# dm64lc_cslr_prev_001 register map
Vendor: Texas Instruments
Peripheral module from a debugger description file.
Registers are 32-bit, access not given, reset 0x0 unless marked. A register's access mark holds for its fields unless they carry their own. Offsets are as the file gives them; lines under a group give offsets from that group; [hi:lo] are bit positions; {n}, {i} and the like mark numbered series; 'fields as' and 'values as' point back to an identical list; <NAME> marks a mode.

## PREV — Preview Engine (spec vesion: 1.00.w.33)
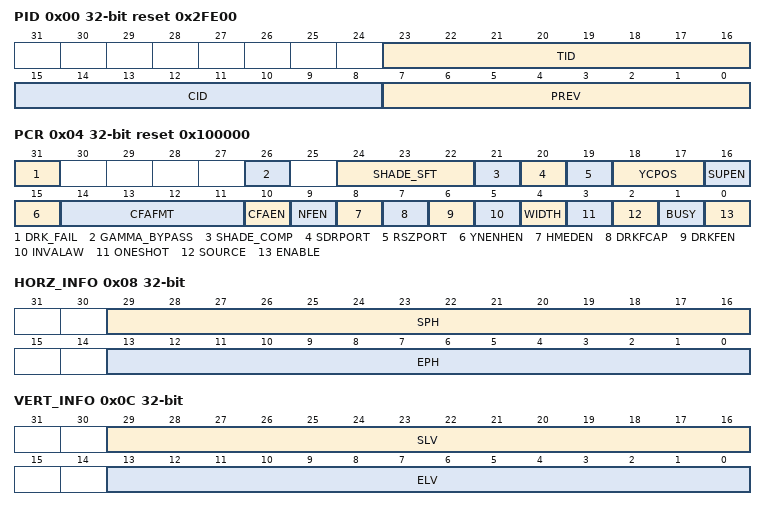
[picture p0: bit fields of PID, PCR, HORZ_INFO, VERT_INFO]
0x00 PID reset 0x2FE00 — Peripheral Revision and Class Information
  [23:16] TID ro — Peripheral Identificiation Preview Engine
  [15:8] CID ro — Class Identification Video Processing Front End (VPFE)
  [7:0] PREV ro — Peripheral Revision Number Initial Revision
0x04 PCR reset 0x100000 — Peripheral Control Register
  [31] DRK_FAIL rw — Dark frame subtract fail status Write 1 to clear this bit: dark frame subtract for current frame is abandoned, dark frame subtract resumes for next frame (but bit is not cleared unless explicitly done by firmware)
    0=PASS (pass flag); 1=FAIL (failed flag)
  [26] GAMMA_BYPASS rw — Gamma table bypass
    0=NO_BYPASS (Gamma tables not bypassed); 1=BYPASS (gamma tables are bypassed (output is 8 MSB or 10-bit input))
  [24:22] SHADE_SFT rw — Shading compensation right shift after multiplication 0-7: bits
  [21] SHADE_COMP rw — Shading compensation enable instead of dark frame The 8-bit value loaded from SDRAM is multiplied with the current pixel instead of subtracting it. Note that the dark frame subtract needs to be enabled in addition to this bit being active to perform shading compensation
    0=DISABLE; 1=ENABLE
  [20] SDRPORT rw — SDRAM port for the output of preview
    0=DISABLE; 1=ENABLE
  [19] RSZPORT rw — Resizer port enable (for input to resizer) Controls whether or not SDRAM output data is forwarded to the resizer input port. This control bit does not depend on the state of the SDRPORT bit above. Data is simultaneously written to SDRAM (if SDRPORT bit is set) while sending the same data to the resizer as input. Note that the CCDC is also capable or directly writing to the resizer input port. The CCDC setting takes precedence over the preview engine setting.
    0=DISABLE; 1=ENABLE
  [18:17] YCPOS rw — YC position
    0=YCRYCB (Y1(31:24) Cr0(23:16) Y0(15:8) Cb0(7:0)); 1=YCBYCR (Y1(31:24) Cb0(23:16) Y0(15:8) Cr0(7:0)); 2=CBYCRY (Cb0(31:24) Y1(23:16) Cr(15:8) Y0(7:0)); 3=CRYCBY (Cr0(31:24) Y1(23:16) Cb0(15:8) Y0(7:0))
  [16] SUPEN rw — Color suppression
    0=DISABLE; 1=ENABLE
  [15] YNENHEN rw — Non-linear enhancer
    0=DISABLE; 1=ENABLE
  [14:11] CFAFMT rw — CFA format
    0=CONV_BAYER (Conventional Bayer pattern); 1=RSV (RESERVED); 2=RSV (RESERVED); 3=V_AND_H_2X_DNSAMPLE (Vertical and horizontal 2x downsample); 4=RSV (RESERVED); 5=RSV (RESERVED)
  [10] CFAEN rw — CFA enable
    0=DISABLE; 1=ENABLE
  [9] NFEN rw — Noise filter (no register impact)
    0=DISABLE; 1=ENABLE
  [8] HMEDEN rw — Horizontal median filter (no register impact)
    0=DISABLE; 1=ENABLE
  [7] DRKFCAP rw — Dark frame capture
    0=NORMAL (normal processing); 1=CAPT_DK_FRM (capture dark frame)
  [6] DRKFEN rw — Subtract dark frame
    0=DISABLE; 1=ENABLE
  [5] INVALAW rw — Inverse A-law
    0=DISABLE; 1=ENABLE
  [4] WIDTH rw — Input data width
    0=10_BITWIDE; 1=8_BITWIDE
  [3] ONESHOT rw — One shot mode *If this bit is set to 1, it will be reset to 0 after the ENABLE bit is asserted.
    0=CONTINUOUS_VIA_VPORT (Continuous mode (via the video port)); 1=ONESHOTMODE
  [2] SOURCE rw — Input source *If this bit is set to 1, it will be reset to 0 after the ENABLE bit is asserted.
    0=VPORT_VIA_CCDC (Video port (via the CCDC)); 1=SDRAM
  [1] BUSY ro — Busy bit
    0=NOTBUSY (Preview engine is not busy); 1=BUSY (Preview engine is busy)
  [0] ENABLE rw — Enable bit *If the ONESHOT or SOURCE bit is 1, this bit will be reset to 0 after it is asserted.
    0=PREV_DISABLE (Preview engine is disabled); 1=PREV_ENABLE (Preview engine is enabled)
0x08 HORZ_INFO — Horizontal information/setup
  [29:16] SPH rw — Start pixel horizontal
  [13:0] EPH rw — End pixel horizontal The input width of the preview engine must be a multiple of the average count multiplied by the least common multiple of the odd distance and even distance of the AVE register settings. HORZ_INFO.EPH - HORZ_INFO.EPH + 1) MOD ((1 << AVE.COUNT) * LeastCommonMultiple(AVE.ODDDIST+1, AVE.EVENDIST+1)) = 0
0x0C VERT_INFO — Vertical information/setup
  [29:16] SLV rw — Start line vertical
  [13:0] ELV rw — End line vertical
0x10 RSDR_ADDR rw — Read address from SDRAM
  [31:0] RADR — Read Address Specifies the initial address of the frame that is to be fetched from SDRAM The lower 5 bits of this register are always treated as zeroes - the starting address should be 32-byte aligned * This field can be altered even when the preview engine is busy. Change will take place only for the next frame. However, note that reading this register will always give the latest value.
0x14 RADR_OFFSET — Line offset for the read data
  [15:0] OFFSET rw — Line offset Specifies the offset for each line relative to the previous line The lower 5 bits of this register are always treated as zeroes - the offset should be 32-byte aligned * This field can be altered even when the preview engine is busy. Change will take place only for the next frame. However, note that reading this register will always give the latest value.
0x18 DSDR_ADDR rw — Dark frame address from SDRAM
  [31:0] DRKF — Read Address Specifies the initial address of the dark frame that is to be fetched from SDRAM The lower 5 bits of this register are always treated as zeroes - the starting address should be 32-byte aligned * This field can be altered even when the preview engine is busy. Change will take place only for the next frame. However, note that reading this register will always give the latest value.
0x1C DRKF_OFFSET — Line offset for the dark frame data
  fields as RADR_OFFSET
0x20 WSDR_ADDR rw — Write address to the sDRAM
  [31:0] ADDR — Write Address Specifies the output address of the frame that is to be stored into the SDRAM/DDRAM The lower 5 bits of this register are always treated as zeroes - the starting address should be 32-byte aligned For optimum performance in the system, the starting address should be on a 256-byte boundary * This field can be altered even when the preview engine is busy. Change will take place only for the next frame. However, note that reading this register will always give the latest value.
0x24 WADD_OFFSET — Line offset for the write data
  [15:0] OFFSET rw — Line offset Specifies the offset for each line relative to the previous line The lower 5 bits of this register are always treated as zeroes - the offset should be 32-byte aligned For optimum performance in the system, the offset should be on a 256-byte boundary * This field can be altered even when the preview engine is busy. Change will take place only for the next frame. However, note that reading this register will always give the latest value.
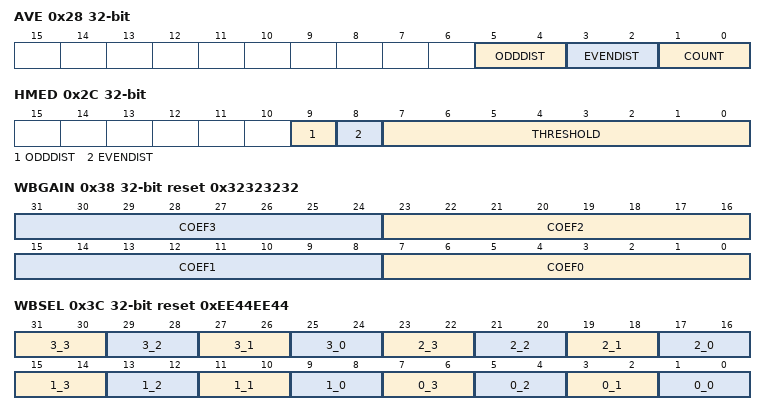
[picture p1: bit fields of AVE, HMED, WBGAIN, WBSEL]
0x28 AVE — Input formatter/averager
  [5:4] ODDDIST rw — Distance between consecutive pixels of same color in the odd line
    0=1PIXEL; 1=2PIXELS; 2=3PIXELS; 3=4PIXELS
  [3:2] EVENDIST rw — Distance between consecutive pixels of same color in the even line
    0=1PIXEL; 1=2PIXELS; 2=3PIXELS; 3=4PIXELS
  [1:0] COUNT rw — Number of horizontal pixels to average This field should not be changed when the PCR.DRKFEN bit is set to '1' The input width must be divisible by the number of horizontal pixels to average indicated by this field (ie. if 4 pixel average is selected, then the input width must be a multiple of 4).
    0=NOAVERAGING; 1=2PIXEL_AVG (2 pixels average); 2=4PIXEL_AVG (4 pixels average); 3=8PIXEL_AVG (8 pixels average)
0x2C HMED — Horizontal median filter
  [9] ODDDIST rw — Distance between consecutive pixels of same color in the odd line
    0=1PIXEL; 1=2PIXELS
  [8] EVENDIST rw — Distance between consecutive pixels of same color in the even line
    0=1PIXEL; 1=2PIXELS
  [7:0] THRESHOLD rw — Horizontal median filter threshold
0x30 NF — Noise filter
  [3:0] STRNGTH rw — Strength to use for the noise filter x = ((x * (16-STRNGTH)) + (ave * STRNGTH)) >> 4
0x34 WB_DGAIN reset 0x256 — White balance digital gain
  [9:0] DGAIN rw — Digital gain for the white balance (U10Q8) can change anytime following the start of a frame
0x38 WBGAIN rw reset 0x32323232 — White balance coefficients
  [8n+7:8n] COEF{n} (n=0..3) — White balance gain - COEF {n} (U8Q5) can change anytime following the start of a frame
0x3C WBSEL rw reset 0xEE44EE44 — White balance coefficients selection
  [all] fields
    {v}=COEF{v} (v=0..3)
  [31:30] 3_3 — Coefficient selection for 3rd line, 3rd pixel
  [29:28] 3_2 — Coefficient selection for 3rd line, 2nd pixel
  [27:26] 3_1 — Coefficient selection for 3rd line, 1st pixel
  [25:24] 3_0 — Coefficient selection for 3rd line, 0th pixel
  [23:22] 2_3 — Coefficient selection for 2nd line, 3rd pixel
  [21:20] 2_2 — Coefficient selection for 2nd line, 2nd pixel
  [19:18] 2_1 — Coefficient selection for 2nd line, 1st pixel
  [17:16] 2_0 — Coefficient selection for 2nd line, 0th pixel
  [15:14] 1_3 — Coefficient selection for 1st line, 3rd pixel
  [13:12] 1_2 — Coefficient selection for 1st line, 2nd pixel
  [11:10] 1_1 — Coefficient selection for 1st line, 1st pixel
  [9:8] 1_0 — Coefficient selection for 1st line, 0th pixel
  [7:6] 0_3 — Coefficient selection for 0th line, 3rd pixel
  [5:4] 0_2 — Coefficient selection for 0th line, 2nd pixel
  [3:2] 0_1 — Coefficient selection for 0th line, 1st pixel
  [1:0] 0_0 — Coefficient selection for 0th line, 0th pixel
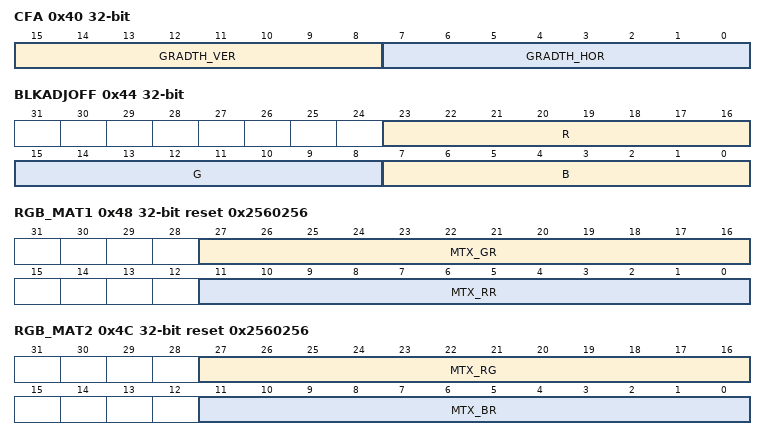
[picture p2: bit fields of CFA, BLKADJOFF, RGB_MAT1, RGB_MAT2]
0x40 CFA
  [15:8] GRADTH_VER rw — Gradient threshold vertical
  [7:0] GRADTH_HOR rw — Gradient threshold horizontal
0x44 BLKADJOFF — Black adjustment offset
  [23:16] R rw — Black level offset adjustment for Red in 2's complement format
  [15:8] G rw — Black level offset adjustment for Green in 2's complement format
  [7:0] B rw — Black level offset adjustment for Blue in 2's complement format
0x48 RGB_MAT1 reset 0x2560256 — RGB2RGB blending matrix coefficients
  [27:16] MTX_GR rw — Blending value for GR position (S12Q8 format)
  [11:0] MTX_RR rw — Blending value for RR position (S12Q8 format)
0x4C RGB_MAT2 reset 0x2560256 — RGB2RGB blending matrix coefficients
  [27:16] MTX_RG rw — Blending value for RG position (S12Q8 format)
  [11:0] MTX_BR rw — Blending value for BR position (S12Q8 format)
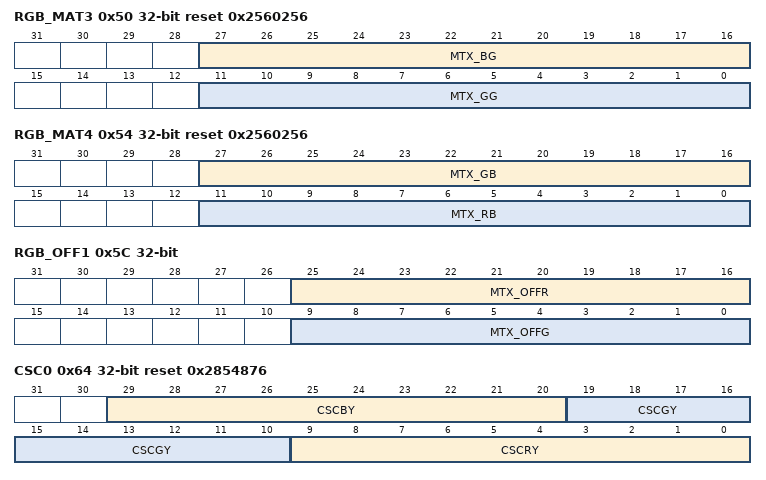
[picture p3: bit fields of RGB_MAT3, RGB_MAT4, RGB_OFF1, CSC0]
0x50 RGB_MAT3 reset 0x2560256 — RGB2RGB blending matrix coefficients
  [27:16] MTX_BG rw — Blending value for BG position (S12Q8 format)
  [11:0] MTX_GG rw — Blending value for GG position (S12Q8 format)
0x54 RGB_MAT4 reset 0x2560256 — RGB2RGB blending matrix coefficients
  [27:16] MTX_GB rw — Blending value for GB position (S12Q8 format)
  [11:0] MTX_RB rw — Blending value for RB position (S12Q8 format)
0x58 RGB_MAT5 reset 0x256 — RGB2RGB blending matrix coefficients
  [11:0] MTX_BB rw — Blending value for BB position (S12Q8 format)
0x5C RGB_OFF1 — RGB2RGB blending matrix offsets
  [25:16] MTX_OFFR rw — Blending Offset value for Red (in two's complement)
  [9:0] MTX_OFFG rw — Blending Offset value for Green (in two's complement)
0x60 RGB_OFF2 — RGB2RGB blending matrix offsets
  [9:0] MTX_OFFB rw — Blending Offset value for Blue (in two's complement)
0x64 CSC0 reset 0x2854876 — Color space conversion coefficients
  [29:20] CSCBY rw — Color Space Conversion Coefficient of B for computing Y Precision is S10Q8
  [19:10] CSCGY rw — Color Space Conversion Coefficient of G for computing Y Precision is S10Q8
  [9:0] CSCRY rw — Color Space Conversion Coefficient of R for computing Y Precision is S10Q8
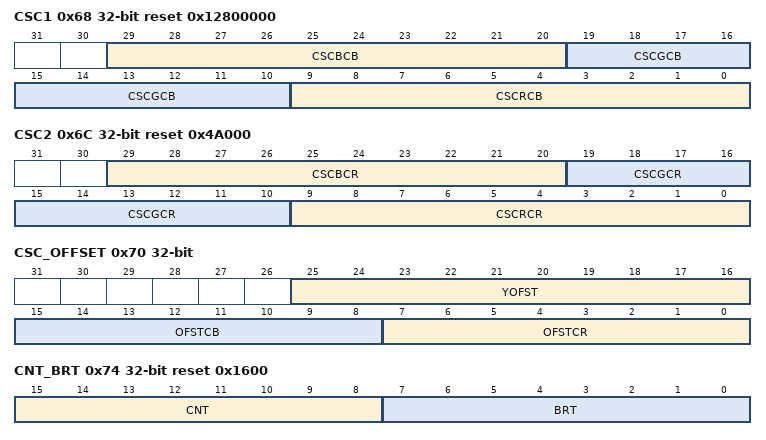
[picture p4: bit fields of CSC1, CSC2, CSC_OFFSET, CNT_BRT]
0x68 CSC1 reset 0x12800000 (reset mask 0xFFF00000) — Color space conversion coefficients
  [29:20] CSCBCB rw — Color Space Conversion Coefficient of R for computing Cr Precision is S10Q8
  [19:10] CSCGCB rw — Color Space Conversion Coefficient of B for computing Cb Precision is S10Q8
  [9:0] CSCRCB rw — Color Space Conversion Coefficient of G for computing Cb Precision is S10Q8
0x6C CSC2 reset 0x4A000 (reset mask 0xC00FFC00) — Color space conversion coefficients
  [29:20] CSCBCR rw — Color Space Conversion Coefficient of B for computing Cr Precision is S10Q8
  [19:10] CSCGCR rw — Color Space Conversion Coefficient of B for computing Cb Precision is S10Q8
  [9:0] CSCRCR rw — Color Space Conversion Coefficient of G for computing Cb Precision is S10Q8
0x70 CSC_OFFSET — Color space conversion offsets
  [25:16] YOFST rw — DC Offset value for Y Yout = Yin + YOFST ( 0-1023)
  [15:8] OFSTCB rw — DC Offset value for Cb (S8Q7) Cout = Cin + OFSTCB ( -128:127 )
  [7:0] OFSTCR rw — DC Offset value for Cr (S8Q7) Cout = Cin + OFSTCR ( -128:127 )
0x74 CNT_BRT reset 0x1600 — Contrast and brightness settings
  [15:8] CNT rw — Contrast Adjustment Sets the contrast of the Y data. Precision is U8Q4, i.e ( 0 to 15.9375 ). Applied after offset adjustments.
  [7:0] BRT rw — Brightness Adjustment Sets the brightness of Y data ( 0 to 255 ). Applied after contrast adjustments.
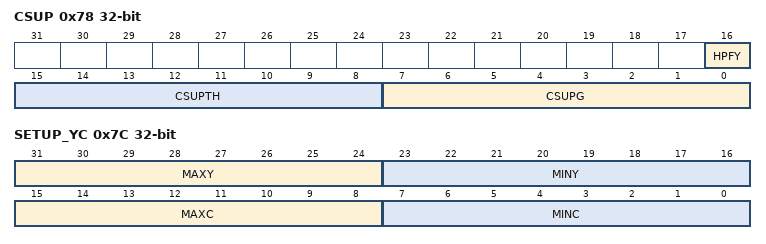
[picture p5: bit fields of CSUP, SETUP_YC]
0x78 CSUP — Chrominance supression settings
  [16] HPFY rw — Use HPF of Luminance for chroma suppression
    0=DISABLE (disable (use Luminance without HPF)); 1=ENABLE
  [15:8] CSUPTH rw — Chroma Suppression Threshold
  [7:0] CSUPG rw — Gain value for Chroma Suppression Function Precision is U8Q8 i.e ( 0 to 0.99609375 )
0x7C SETUP_YC rw (reset mask 0xFF00FF) — Maximum/Minimum Y and C settings
  [31:24] MAXY — Maximum Y value, values greater than set value are clipped to the set value
  [23:16] MINY — Minimum Y value. Values less than set value are clipped to the set value
  [15:8] MAXC — Maximum Cb and Cr value, values greater than set value are clipped to the set value
  [7:0] MINC — Minimum Cb and Cr value. Values less than set value are clipped to the set value
0x80 SET_TBL_ADDRESS — Setup Table addresses
  [12:0] ADDR rw — 13-bit address
0x84 SET_TBL_DATA — Setup Table data
  [19:0] DATA rw — Data to be written All 20-bits are valid for the non-linear enhancer Only 8 LSB are chosen for the gamma, noise filter, and CFA coefficient tables
